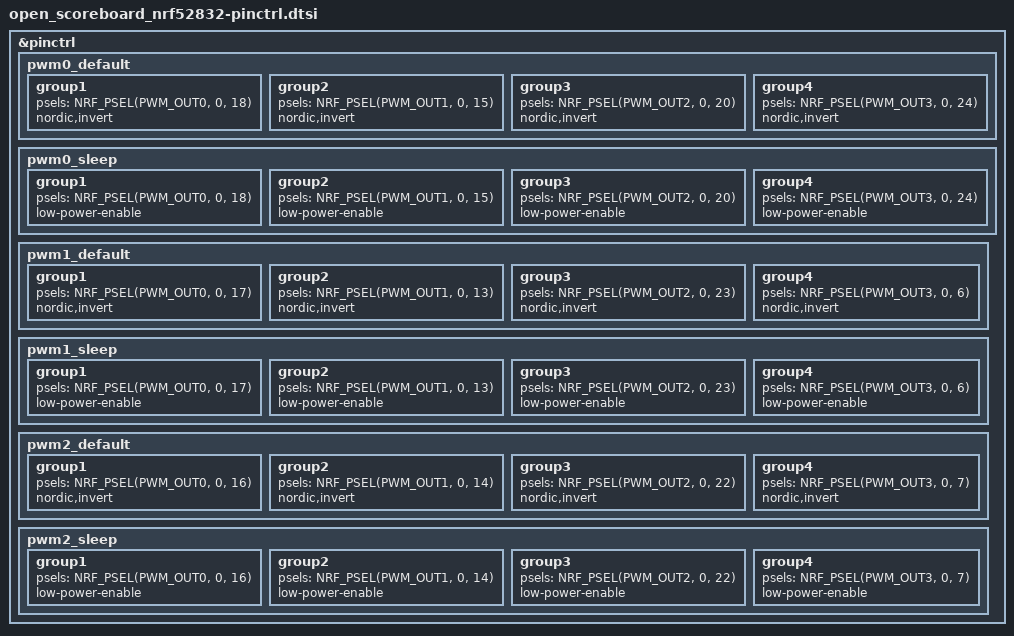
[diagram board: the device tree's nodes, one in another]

 &pinctrl {

    pwm0_default: pwm0_default {
        group1 {
            psels = <NRF_PSEL(PWM_OUT0, 0, 18)>;
            nordic,invert;
        };
        group2{
            psels = <NRF_PSEL(PWM_OUT1, 0, 15)>;
            nordic,invert;
        };
        group3 {
            psels = <NRF_PSEL(PWM_OUT2, 0, 20)>;
            nordic,invert;
        };
        group4{
            psels = <NRF_PSEL(PWM_OUT3, 0, 24)>;
            nordic,invert;
        };
    };
    
    pwm0_sleep: pwm0_sleep {
        group1 {
            psels = <NRF_PSEL(PWM_OUT0, 0, 18)>;
            low-power-enable;
        };
        group2{
            psels = <NRF_PSEL(PWM_OUT1, 0, 15)>;
            low-power-enable;
        };
        group3 {
            psels = <NRF_PSEL(PWM_OUT2, 0, 20)>;
            low-power-enable;
        };
        group4{
            psels = <NRF_PSEL(PWM_OUT3, 0, 24)>;
            low-power-enable;
        };
    };

    pwm1_default: pwm1_default {
        group1 {
            psels = <NRF_PSEL(PWM_OUT0, 0, 17)>;
            nordic,invert;
        };
        group2{
            psels = <NRF_PSEL(PWM_OUT1, 0, 13)>;
            nordic,invert;
        };
        group3 {
            psels = <NRF_PSEL(PWM_OUT2, 0, 23)>;
            nordic,invert;
        };
        group4{
            psels = <NRF_PSEL(PWM_OUT3, 0, 6)>;
            nordic,invert;
        };
    };
    
    pwm1_sleep: pwm1_sleep {
        group1 {
            psels = <NRF_PSEL(PWM_OUT0, 0, 17)>;
            low-power-enable;
        };
        group2{
            psels = <NRF_PSEL(PWM_OUT1, 0, 13)>;
            low-power-enable;
        };
        group3 {
            psels = <NRF_PSEL(PWM_OUT2, 0, 23)>;
            low-power-enable;
        };
        group4{
            psels = <NRF_PSEL(PWM_OUT3, 0, 6)>;
            low-power-enable;
        };
    };

    pwm2_default: pwm2_default {
        group1 {
            psels = <NRF_PSEL(PWM_OUT0, 0, 16)>;
            nordic,invert;
        };
        group2{
            psels = <NRF_PSEL(PWM_OUT1, 0, 14)>;
            nordic,invert;
        };
        group3 {
            psels = <NRF_PSEL(PWM_OUT2, 0, 22)>;
            nordic,invert;
        };
        group4{
            psels = <NRF_PSEL(PWM_OUT3, 0, 7)>;
            nordic,invert;
        };
    };
    
    pwm2_sleep: pwm2_sleep {
        group1 {
            psels = <NRF_PSEL(PWM_OUT0, 0, 16)>;
            low-power-enable;
        };
        group2{
            psels = <NRF_PSEL(PWM_OUT1, 0, 14)>;
            low-power-enable;
        };
        group3 {
            psels = <NRF_PSEL(PWM_OUT2, 0, 22)>;
            low-power-enable;
        };
        group4{
            psels = <NRF_PSEL(PWM_OUT3, 0, 7)>;
            low-power-enable;
        };
    };



 };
